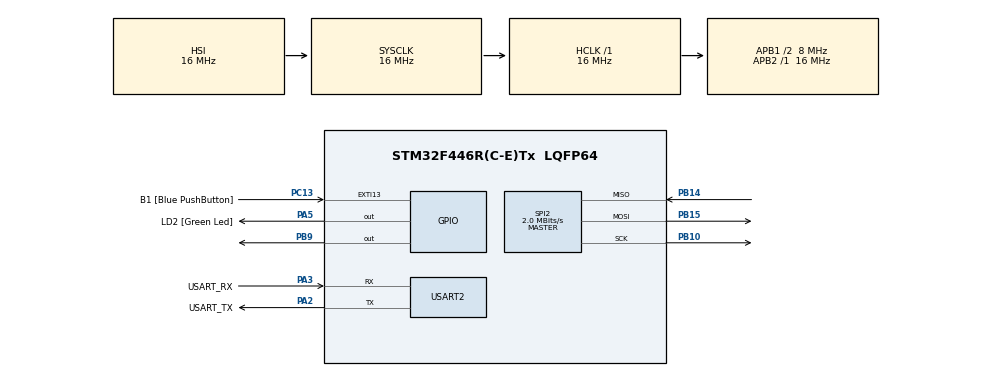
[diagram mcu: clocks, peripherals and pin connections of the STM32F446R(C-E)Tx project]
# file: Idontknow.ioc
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Mcu.Family=STM32F4
Mcu.Name=STM32F446R(C-E)Tx
Mcu.Package=LQFP64
NVIC.PriorityGroup=NVIC_PRIORITYGROUP_0
PA13.GPIO_Label=TMS
PA13.Mode=Serial_Wire
PA13.Signal=SYS_JTMS-SWDIO
PA14.GPIO_Label=TCK
PA14.Mode=Serial_Wire
PA14.Signal=SYS_JTCK-SWCLK
PA2.GPIO_Label=USART_TX
PA2.Mode=Asynchronous
PA2.Signal=USART2_TX
PA3.GPIO_Label=USART_RX
PA3.Mode=Asynchronous
PA3.Signal=USART2_RX
PA5.GPIO_Label=LD2 [Green Led]
PA5.Signal=GPIO_Output
PB10.GPIO_PuPd=GPIO_PULLUP
PB10.Mode=Full_Duplex_Master
PB10.Signal=SPI2_SCK
PB14.GPIO_PuPd=GPIO_PULLUP
PB14.Mode=Full_Duplex_Master
PB14.Signal=SPI2_MISO
PB15.GPIO_PuPd=GPIO_PULLUP
PB15.Mode=Full_Duplex_Master
PB15.Signal=SPI2_MOSI
PB3.GPIO_Label=SWO
PB3.Signal=SYS_JTDO-SWO
PB9.GPIO_PuPd=GPIO_PULLUP
PB9.GPIO_Speed=GPIO_SPEED_FREQ_VERY_HIGH
PB9.PinState=GPIO_PIN_SET
PB9.Signal=GPIO_Output
PC13.GPIO_Label=B1 [Blue PushButton]
PC13.GPIO_ModeDefaultEXTI=GPIO_MODE_IT_FALLING
PC13.Signal=GPXTI13
PC14-OSC32_IN.Mode=LSE-External-Oscillator
PC14-OSC32_IN.Signal=RCC_OSC32_IN
PC15-OSC32_OUT.Mode=LSE-External-Oscillator
PC15-OSC32_OUT.Signal=RCC_OSC32_OUT
PH0-OSC_IN.Mode=HSE-External-Oscillator
PH0-OSC_IN.Signal=RCC_OSC_IN
PH1-OSC_OUT.Mode=HSE-External-Oscillator
PH1-OSC_OUT.Signal=RCC_OSC_OUT
ProjectManager.HeapSize=0x200
ProjectManager.StackSize=0x400
ProjectManager.TargetToolchain=Makefile
RCC.48MHZClocksFreq_Value=84000000
RCC.AHBFreq_Value=16000000
RCC.APB1CLKDivider=RCC_HCLK_DIV2
RCC.APB1Freq_Value=8000000
RCC.APB1TimFreq_Value=16000000
RCC.APB2Freq_Value=16000000
RCC.APB2TimFreq_Value=16000000
RCC.CortexFreq_Value=16000000
RCC.FLatency-AdvancedSettings=FLASH_LATENCY_0
RCC.HCLKFreq_Value=16000000
RCC.HSE_VALUE=8000000
RCC.HSI_VALUE=16000000
RCC.PLLN=336
RCC.PLLP=RCC_PLLP_DIV4
RCC.PLLSourceVirtual=RCC_PLLSOURCE_HSE
RCC.SYSCLKFreq_VALUE=16000000
RCC.USBFreq_Value=84000000
RCC.VCOOutputFreq_Value=168000000
SPI2.BaudRatePrescaler=SPI_BAUDRATEPRESCALER_4
SPI2.CLKPhase=SPI_PHASE_2EDGE
SPI2.CLKPolarity=SPI_POLARITY_HIGH
SPI2.CalculateBaudRate=2.0 MBits/s
SPI2.DataSize=SPI_DATASIZE_8BIT
SPI2.Direction=SPI_DIRECTION_2LINES
SPI2.Mode=SPI_MODE_MASTER
SPI2.TIMode=SPI_TIMODE_DISABLE
SPI2.VirtualType=VM_MASTER
USART2.VirtualMode=VM_ASYNC
board=NUCLEO-F446RE

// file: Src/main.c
/* USER CODE BEGIN Header */
/**
 ******************************************************************************
 * @file           : main.c
 * @brief          : Main program body
 ******************************************************************************
 * @attention
 *
 * <h2><center>&copy; Copyright (c) 2019 STMicroelectronics.
 * All rights reserved.</center></h2>
 *
 * This software component is licensed by ST under BSD 3-Clause license,
 * the "License"; You may not use this file except in compliance with the
 * License. You may obtain a copy of the License at:
 *                        opensource.org/licenses/BSD-3-Clause
 *
 ******************************************************************************
 */
/* USER CODE END Header */

#include "main.h"
#include "spi.h"
#include "usart.h"
#include "gpio.h"
#include "lsm6ds3.h"

/* USER CODE BEGIN Includes */
// SPI_HandleTypeDef hspi2;

/* USER CODE END Includes */

void SystemClock_Config(void);

int main(void)
{

  /* MCU Configuration--------------------------------------------------------*/

  /* Reset of all peripherals, Initializes the Flash interface and the Systick. */
  HAL_Init();

  /* Configure the system clock */
  SystemClock_Config();

  /* Initialize all configured peripherals */
  MX_GPIO_Init();
  MX_USART2_UART_Init();
  MX_SPI2_Init();
  /* USER CODE BEGIN 2 */

  // unread_data and address for using lsm6ds3 in the main loop
  volatile uint8_t unread_data;
  uint8_t addr;
  // data in circular buffer
  sensor_data_t data[1024];
  uint16_t dptr = 0;
  NAP_SPI_INIT_LSM6DS3(0);
  /* USER CODE END 2 */
  // HAL_UART_Transmit(&huart2,&unread_data, 1, 0xff);
  // HAL_UART_Transmit(&huart2,text_data,sizeof(text_data), 0xff);

  /* Infinite loop */
  /* USER CODE BEGIN WHILE */
  while (1)
  {

    // check fifo status for unread data
    addr = STATUS_REG;
    NAP_SPI_Read(&hspi2, &addr, &unread_data);

    // if data available on all shit
    if(unread_data)
    {
      data[dptr++] = NAP_SPI_GetData();
      transmit_sensordata(data[dptr-1]);
      HAL_Delay(500);
      if(dptr> 1023)
      {
        //transmit_buffer(data, dptr);
        dptr = 0;
      }
    }
  }

  /* USER CODE END WHILE */
  //    NAP_SPI_Check_Fifo(&remainder);
  //    NAP_SPI_Read(&hspi2,&addr,&unread_data);
  //    HAL_UART_Transmit(&huart2,&unread_data, 1, 0xff);
  //    HAL_UART_Transmit(&huart2,text_data,sizeof(text_data), 0xff);
  //    /* USER CODE BEGIN 3 */

  /* USER CODE END 3 */
}

void SystemClock_Config(void)
{
  RCC_OscInitTypeDef RCC_OscInitStruct = {0};
  RCC_ClkInitTypeDef RCC_ClkInitStruct = {0};

  /** Configure the main internal regulator output voltage
   */
  __HAL_RCC_PWR_CLK_ENABLE();
  __HAL_PWR_VOLTAGESCALING_CONFIG(PWR_REGULATOR_VOLTAGE_SCALE3);
  /** Initializes the CPU, AHB and APB busses clocks
   */
  RCC_OscInitStruct.OscillatorType = RCC_OSCILLATORTYPE_HSI;
  RCC_OscInitStruct.HSIState = RCC_HSI_ON;
  RCC_OscInitStruct.HSICalibrationValue = RCC_HSICALIBRATION_DEFAULT;
  RCC_OscInitStruct.PLL.PLLState = RCC_PLL_NONE;
  if (HAL_RCC_OscConfig(&RCC_OscInitStruct) != HAL_OK)
  {
    Error_Handler();
  }
  /** Initializes the CPU, AHB and APB busses clocks
   */
  RCC_ClkInitStruct.ClockType = RCC_CLOCKTYPE_HCLK|RCC_CLOCKTYPE_SYSCLK
    |RCC_CLOCKTYPE_PCLK1|RCC_CLOCKTYPE_PCLK2;
  RCC_ClkInitStruct.SYSCLKSource = RCC_SYSCLKSOURCE_HSI;
  RCC_ClkInitStruct.AHBCLKDivider = RCC_SYSCLK_DIV1;
  RCC_ClkInitStruct.APB1CLKDivider = RCC_HCLK_DIV2;
  RCC_ClkInitStruct.APB2CLKDivider = RCC_HCLK_DIV1;

  if (HAL_RCC_ClockConfig(&RCC_ClkInitStruct, FLASH_LATENCY_0) != HAL_OK)
  {
    Error_Handler();
  }
}

void Error_Handler(void)
{
  /* USER CODE BEGIN Error_Handler_Debug */
  /* User can add his own implementation to report the HAL error return state */
  int a = 0;
  /* USER CODE END Error_Handler_Debug */
}

/************************ (C) COPYRIGHT STMicroelectronics *****END OF FILE****/
